# FEATURES register map
Vendor: EmbLinkOs; File version: 1.0
A device made of SVD features
CPU: CM4 r0p1, little endian, MPU, FPU, 3 interrupt priority bits
Registers are 32-bit, read-write, reset 0x0 unless marked. A register's access mark holds for its fields unless they carry their own. Offsets are from the block's base; lines under a group give offsets from that group; [hi:lo] are bit positions; {n}, {i} and the like mark numbered series; 'fields as' and 'values as' point back to an identical list; <NAME> marks a mode.

## Memory map
0x40001000 DMA size 0x400 — DMA controller
0x40002000 NET — Network interface
0x40003000 NET2
{0x40004000+0x400*n} TIMER{n} (n=0..2) — Timer

## Interrupts
5 DMA — DMA channel done
6 NET
7 NET2

## DMA — DMA controller
Base 0x40001000
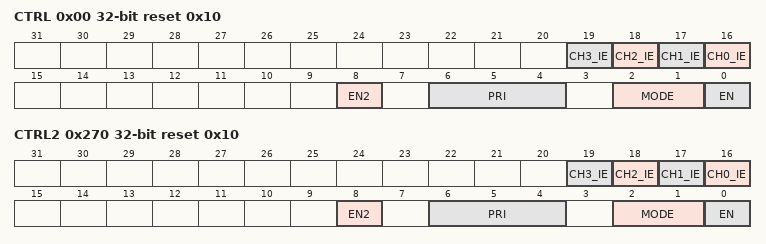
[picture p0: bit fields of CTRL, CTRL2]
0x00 CTRL reset 0x10 — Control
  [n+16] CH{n}_IE (n=0..3) — Channel interrupt enable
  [8] EN2 — Second enable
    0=Disabled; 1=Enabled
  [6:4] PRI — Priority
    0=Disabled; 1=Enabled
  [2:1] MODE ro
    on read: 0=Single; 0b1x=Burst; other=Other
  [0] EN — Enable
    0=Disabled; 1=Enabled
0x04 STATUS ro
0x04 CLEAR wo — Clear status
{0x100+0x20*i} CH[{i}] (i=0..3) group — Channel
  0x00 SRC — Source
  0x04 DST — Destination
  0x08 CNT 16-bit — Count
  0x0C CFG — Configuration
{0x200+4i} DATA[{i}] (i=0..3) — Data, a C array
{0x210+8i} PRIO[{i}] (i=0..2) — Priority, 8 bytes apart
0x230 GPIO{x}_CTRL (x=A,B,C; step 0x4) — Port control
{0x220+4i} IRQ{i} (i=8..15) — Interrupt line
0x260 MODE{x} (x=A,B,C,D; step 0x2) 16-bit — Lane mode
0x270 CTRL2 reset 0x10 — Control, again
  fields as CTRL
0x280 DATAX — One more data register

## NET — Network interface
Base 0x40002000
Same registers: NET2 0x40003000
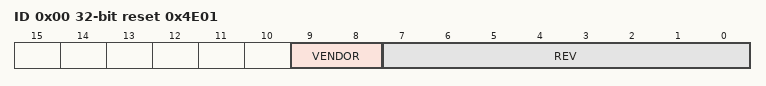
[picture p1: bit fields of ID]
0x00 ID ro reset 0x4E01 — Identification
  [9:8] VENDOR
    on read: 0=Single; 0b1x=Burst; other=Other
  [7:0] REV
{0x100+0x100*i} PORT[{i}] (i=0..1) group
  0x00 CFG — Port configuration
    [1:0] SPEED
  {0x10+0x20*j} QUEUE[{j}] (j=0..3) group
    0x00 HEAD
    0x04 TAIL
    {0x8+8k} DESC[{k}] (k=0..1) group — Descriptor
      0x00 ADDR
      0x04 LEN 16-bit
        [11:0] N
      0x06 FLAGS 16-bit
  0x90 STAT group — Counters
    0x00 RX 16-bit ro
    0x02 TX 16-bit ro
0x400 LANE{x} (x=L,R; step 0x10) group
  0x00 EN
  0x04 LVL
0x500 SPARE group — A spare lane
0x600 MODE_A group — The block in mode A
  0x00 REGA
  0x04 REGB
0x600 MODE_B group (alternate view of MODE_A) — The block in mode B
  0x00 X
  0x04 Y
  0x08 Z
0x610 AFTER

## TIMER{n} — Timer
Base 0x40004000; array of 3, step 0x400
0x00 LOAD
0x04 VAL ro
{0x10+4i} CC[{i}] (i=0..3) group — Capture/compare
  0x00 VALUE
0x20 COPY — Like a port's CFG
  [1:0] SPEED
0x30 LANEX group — A lane of its own
